# GD32W515Tx register map
File version: 1.0
CPU: CM33 r0p0, little endian, MPU, FPU, 4 interrupt priority bits
Registers are 32-bit, read-write, reset 0x0 unless marked. A register's access mark holds for its fields unless they carry their own. Offsets are from the block's base; [hi:lo] are bit positions; lines under a group give offsets from that group; {n}, {i} and the like mark numbered series.

## TIMER16 — General-purpose-timers
Base 0x40018400
Same registers: TIMER15 0x40018000, SEC_TIMER15 0x50018000, SEC_TIMER16 0x50018400
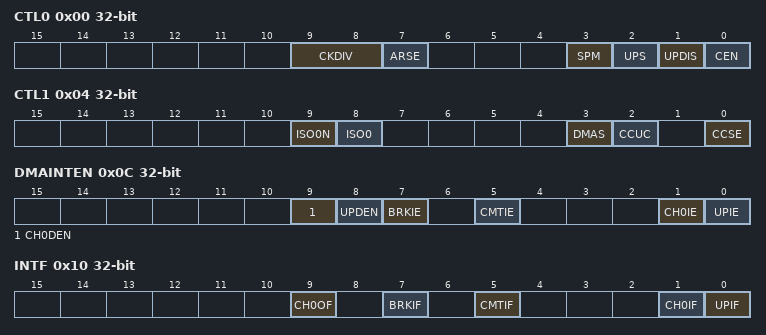
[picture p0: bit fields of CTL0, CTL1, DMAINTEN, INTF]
0x00 CTL0 — control register 0
  [9:8] CKDIV — Clock division
  [7] ARSE — Auto-reload preload enable
  [3] SPM — One-pulse mode
  [2] UPS — Update request source
  [1] UPDIS — Update disable
  [0] CEN — Counter enable
0x04 CTL1 — control register 1
  [9] ISO0N — Output Idle state 0
  [8] ISO0 — Output Idle state 0
  [3] DMAS — Capture/compare DMA selection
  [2] CCUC — Capture/compare control update selection
  [0] CCSE — Capture/compare preloaded control
0x0C DMAINTEN — DMA/Interrupt enable register
  [9] CH0DEN — Capture/Compare 0 DMA request enable
  [8] UPDEN — Update DMA request enable
  [7] BRKIE — Break interrupt enable
  [5] CMTIE — COM interrupt enable
  [1] CH0IE — Capture/Compare 0 interrupt enable
  [0] UPIE — Update interrupt enable
0x10 INTF — interrupt flag register
  [9] CH0OF — Capture/Compare 0 overcapture flag
  [7] BRKIF — Break interrupt flag
  [5] CMTIF — COM interrupt flag
  [1] CH0IF — Capture/compare 0 interrupt flag
  [0] UPIF — Update interrupt flag
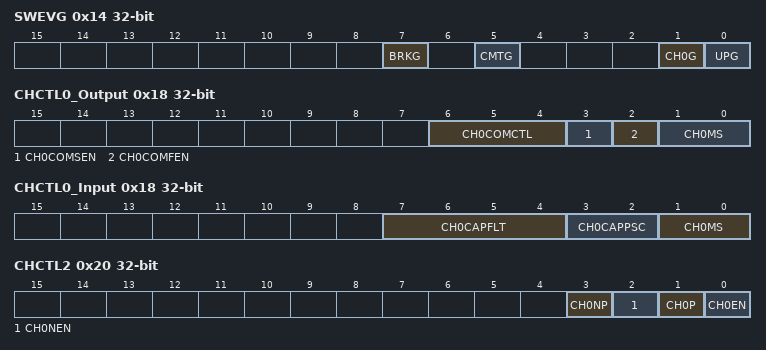
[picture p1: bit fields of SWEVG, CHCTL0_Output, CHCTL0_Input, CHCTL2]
0x14 SWEVG wo — event generation register
  [7] BRKG — Break generation
  [5] CMTG — Capture/Compare control update generation
  [1] CH0G — Capture/compare 0 generation
  [0] UPG — Update generation
0x18 CHCTL0_Output — capture/compare mode register (output mode)
  [6:4] CH0COMCTL — Output Compare 0 mode
  [3] CH0COMSEN — Output Compare 0 preload enable
  [2] CH0COMFEN — Output Compare 0 fast enable
  [1:0] CH0MS — Capture/Compare 0 selection
0x18 CHCTL0_Input (alternate view of CHCTL0_Output) — capture/compare mode register 0 (input mode)
  [7:4] CH0CAPFLT — Input capture 0 filter
  [3:2] CH0CAPPSC — Input capture 0 prescaler
  [1:0] CH0MS — Capture/Compare 0 selection
0x20 CHCTL2 — capture/compare enable register
  [3] CH0NP — Capture/Compare 0 output Polarity
  [2] CH0NEN — Capture/Compare 0 complementary output enable
  [1] CH0P — Capture/Compare 0 output Polarity
  [0] CH0EN — Capture/Compare 0 output enable
0x24 CNT — counter
  [15:0] CNT — counter value
0x28 PSC — prescaler
  [15:0] PSC — Prescaler value
0x2C CAR — auto-reload register
  [15:0] CARL — Auto-reload value
0x30 CREP — repetition counter register
  [7:0] CREP — Repetition counter value
0x34 CH0CV — capture/compare register 0
  [15:0] CH0VAL — Capture/Compare 0 value
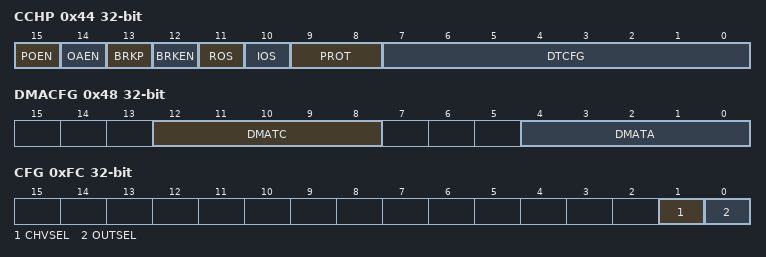
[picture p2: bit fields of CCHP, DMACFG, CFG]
0x44 CCHP — break and dead-time register
  [15] POEN — Main output enable
  [14] OAEN — Automatic output enable
  [13] BRKP — Break polarity
  [12] BRKEN — Break enable
  [11] ROS — Off-state selection for Run mode
  [10] IOS — Off-state selection for Idle mode
  [9:8] PROT — complementary register protect control
  [7:0] DTCFG — Dead-time generator setup
0x48 DMACFG — DMA configuration register
  [12:8] DMATC — DMA transfer count
  [4:0] DMATA — DMA transfer access start address
0x4C DMATB — DMA transfer buffer register
  [15:0] DMATB — DMA register for burst accesses
0xFC CFG — configuration register
  [1] CHVSEL — Write CHxVAL register selection
  [0] OUTSEL — The output value selection

## TSI — Touch sensing Interface
Base 0x40024000
Same registers: SEC_TSI 0x50024000
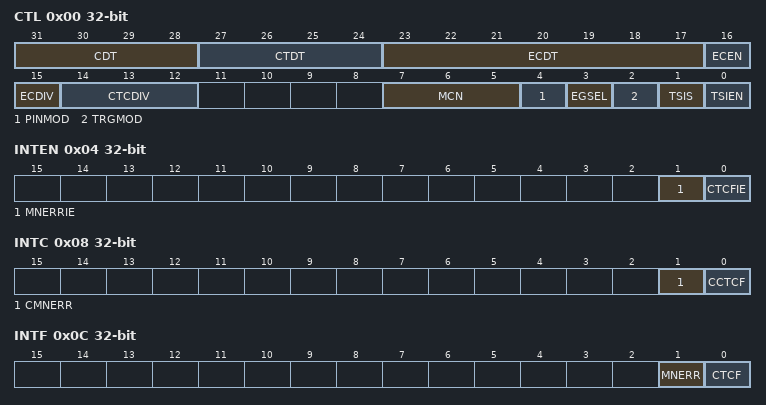
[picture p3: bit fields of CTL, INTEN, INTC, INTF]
0x00 CTL — control register
  [31:28] CDT — Charge transfer pulse high
  [27:24] CTDT — Charge transfer pulse low
  [23:17] ECDT — Spread spectrum deviation
  [16] ECEN — Spread spectrum enable
  [15] ECDIV — Spread spectrum prescaler
  [14:12] CTCDIV — pulse generator prescaler
  [7:5] MCN — Max count value
  [4] PINMOD — I/O Default mode
  [3] EGSEL — Edge selection
  [2] TRGMOD — Trigger mode selection
  [1] TSIS — Start a new acquisition
  [0] TSIEN — Touch sensing controller enable
0x04 INTEN — interrupt enable register
  [1] MNERRIE — Max Cycle Number Error Interrupt Enable
  [0] CTCFIE — Charge-transfer complete flag Interrupt Enable
0x08 INTC wo — interrupt flag clear register
  [1] CMNERR — Clear max cycle number error
  [0] CCTCF — Clear charge-transfer complete flag
0x0C INTF ro — interrupt flag register
  [1] MNERR — Max count error flag
  [0] CTCF — End of acquisition flag
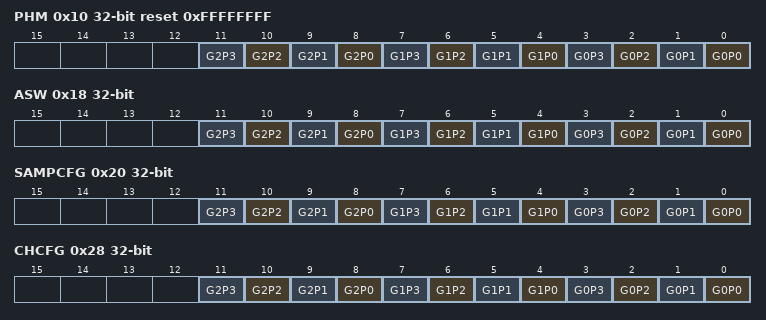
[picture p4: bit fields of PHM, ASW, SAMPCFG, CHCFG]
0x10 PHM reset 0xFFFFFFFF — Pin hysteresis mode register
  [n+8] G2P{n} (n=0..3) — G2P{n} Schmitt trigger hysteresis mode
  [n+4] G1P{n} (n=0..3) — G1P{n} Schmitt trigger hysteresis mode
  [n] G0P{n} (n=0..3) — G0P{n} Schmitt trigger hysteresis mode
0x18 ASW — I/O analog switch register
  [n+8] G2P{n} (n=0..3) — G2P{n} analog switch enable
  [n+4] G1P{n} (n=0..3) — G1P{n} analog switch enable
  [n] G0P{n} (n=0..3) — G0P{n} analog switch enable
0x20 SAMPCFG — I/O sample configuration register
  [n+8] G2P{n} (n=0..3) — G2P{n} sampling mode
  [n+4] G1P{n} (n=0..3) — G1P{n} sampling mode
  [n] G0P{n} (n=0..3) — G0P{n} sampling mode
0x28 CHCFG — I/O channel configuration register
  [n+8] G2P{n} (n=0..3) — G2P{n} channel mode
  [n+4] G1P{n} (n=0..3) — G1P{n} channel mode
  [n] G0P{n} (n=0..3) — G0P{n} channel mode
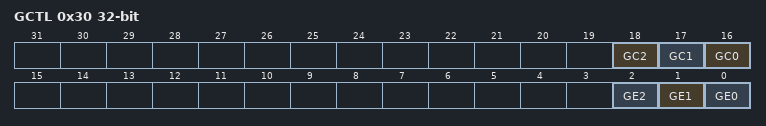
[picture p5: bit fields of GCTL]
0x30 GCTL access per field — I/O group control register
  [18] GC2 ro — Analog I/O group x status
  [17] GC1 ro — Analog I/O group x status
  [16] GC0 ro — Analog I/O group x status
  [2] GE2 rw — Analog I/O group x enable
  [1] GE1 rw — Analog I/O group x enable
  [0] GE0 rw — Analog I/O group x enable
{0x34+4i} G{i}CYCN (i=0..2) — I/O group x cycle number register
  [13:0] CYCN — Cycle number
